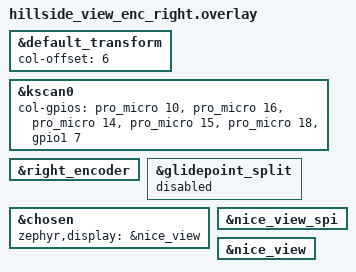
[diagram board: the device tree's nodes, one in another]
/*
 * Copyright (c) 2022 The ZMK Contributors
 *
 * SPDX-License-Identifier: MIT
 */

#include "../hillside_view/hillside_view.dtsi"

&default_transform {
  col-offset = <6>;
};

&kscan0 {
  col-gpios
    = <&pro_micro 10 GPIO_ACTIVE_HIGH>
    , <&pro_micro 16 GPIO_ACTIVE_HIGH>
    , <&pro_micro 14 GPIO_ACTIVE_HIGH>
    , <&pro_micro 15 GPIO_ACTIVE_HIGH>
    , <&pro_micro 18 GPIO_ACTIVE_HIGH>
    , <&gpio1 7 GPIO_ACTIVE_HIGH>
    ;
};

&right_encoder {
  status = "okay";
};

&glidepoint_split {
  status = "disabled";
};

&chosen {
  zephyr,display = &nice_view;
};

&nice_view_spi {
  status = "okay";
};

&nice_view {
  status = "okay";
};
